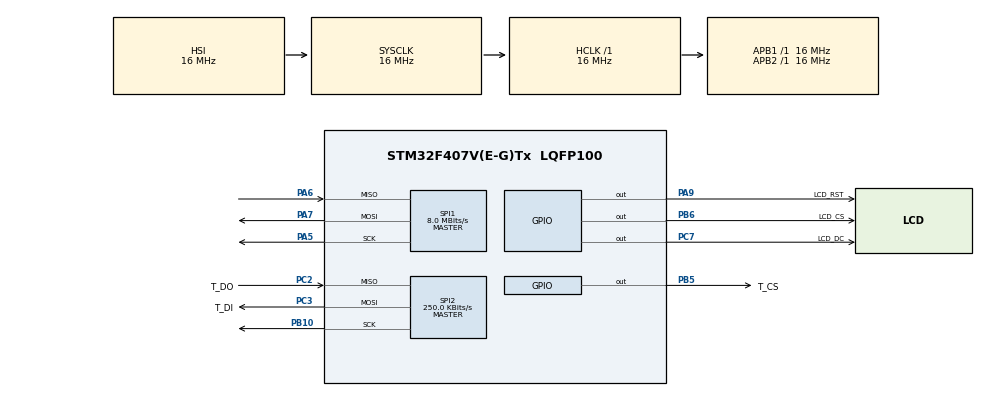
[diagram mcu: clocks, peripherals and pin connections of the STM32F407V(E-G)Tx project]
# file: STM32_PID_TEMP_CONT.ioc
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Mcu.Family=STM32F4
Mcu.Name=STM32F407V(E-G)Tx
Mcu.Package=LQFP100
NVIC.PriorityGroup=NVIC_PRIORITYGROUP_4
PA5.Mode=Full_Duplex_Master
PA5.Signal=SPI1_SCK
PA6.Mode=Full_Duplex_Master
PA6.Signal=SPI1_MISO
PA7.Mode=Full_Duplex_Master
PA7.Signal=SPI1_MOSI
PA9.GPIO_Label=LCD_RST
PA9.Signal=GPIO_Output
PB10.Mode=Full_Duplex_Master
PB10.Signal=SPI2_SCK
PB5.GPIO_Label=T_CS
PB5.Signal=GPIO_Output
PB6.GPIO_Label=LCD_CS
PB6.Signal=GPIO_Output
PC2.GPIO_Label=T_DO
PC2.Mode=Full_Duplex_Master
PC2.Signal=SPI2_MISO
PC3.GPIO_Label=T_DI
PC3.Mode=Full_Duplex_Master
PC3.Signal=SPI2_MOSI
PC7.GPIO_Label=LCD_DC
PC7.Signal=GPIO_Output
ProjectManager.HeapSize=0x200
ProjectManager.StackSize=0x400
ProjectManager.TargetToolchain=STM32CubeIDE
RCC.AHBFreq_Value=16000000
RCC.APB1Freq_Value=16000000
RCC.APB2Freq_Value=16000000
RCC.CortexFreq_Value=16000000
RCC.HSE_VALUE=25000000
RCC.HSI_VALUE=16000000
RCC.LSE_VALUE=32768
RCC.SYSCLKFreq_VALUE=16000000
RCC.VCOOutputFreq_Value=192000000
SPI1.CalculateBaudRate=8.0 MBits/s
SPI1.Direction=SPI_DIRECTION_2LINES
SPI1.Mode=SPI_MODE_MASTER
SPI1.VirtualType=VM_MASTER
SPI2.BaudRatePrescaler=SPI_BAUDRATEPRESCALER_64
SPI2.CalculateBaudRate=250.0 KBits/s
SPI2.Direction=SPI_DIRECTION_2LINES
SPI2.Mode=SPI_MODE_MASTER
SPI2.VirtualType=VM_MASTER
board=custom

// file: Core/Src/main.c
/* USER CODE BEGIN Header */
/**
  ******************************************************************************
  * @file           : main.c
  * @brief          : Main program body
  ******************************************************************************
  * @attention
  *
  * Copyright (c) 2024 STMicroelectronics.
  * All rights reserved.
  *
  * This software is licensed under terms that can be found in the LICENSE file
  * in the root directory of this software component.
  * If no LICENSE file comes with this software, it is provided AS-IS.
  *
  ******************************************************************************
  */
/* USER CODE END Header */
#include "main.h"
#include "stm32f4xx_hal.h"

/* USER CODE BEGIN Includes */
#include "MY_ILI9341.h"
#include "TSC2046.h"
/* USER CODE END Includes */

SPI_HandleTypeDef hspi1;
SPI_HandleTypeDef hspi2;

void SystemClock_Config(void);
static void MX_GPIO_Init(void);
static void MX_SPI1_Init(void);
static void MX_SPI2_Init(void);

int main(void)
{

  /* MCU Configuration--------------------------------------------------------*/

  /* Reset of all peripherals, Initializes the Flash interface and the Systick. */
  HAL_Init();

  /* Configure the system clock */
  SystemClock_Config();

  /* Initialize all configured peripherals */
  MX_GPIO_Init();
  MX_SPI1_Init();
  MX_SPI2_Init();
  /* USER CODE BEGIN 2 */
  ILI9341_Init(&hspi1, LCD_CS_GPIO_Port, LCD_CS_Pin, LCD_DC_GPIO_Port, LCD_DC_Pin, LCD_RST_GPIO_Port, LCD_RST_Pin);
  ILI9341_setRotation(2);
  ILI9341_Fill(COLOR_MAGENTA);

  /* USER CODE END 2 */

  /* Infinite loop */
  while (1)
  {

  }
}

void SystemClock_Config(void)
{
  RCC_OscInitTypeDef RCC_OscInitStruct = {0};
  RCC_ClkInitTypeDef RCC_ClkInitStruct = {0};

  /** Configure the main internal regulator output voltage
  */
  __HAL_RCC_PWR_CLK_ENABLE();
  __HAL_PWR_VOLTAGESCALING_CONFIG(PWR_REGULATOR_VOLTAGE_SCALE1);

  /** Initializes the RCC Oscillators according to the specified parameters
  * in the RCC_OscInitTypeDef structure.
  */
  RCC_OscInitStruct.OscillatorType = RCC_OSCILLATORTYPE_HSI;
  RCC_OscInitStruct.HSIState = RCC_HSI_ON;
  RCC_OscInitStruct.HSICalibrationValue = RCC_HSICALIBRATION_DEFAULT;
  RCC_OscInitStruct.PLL.PLLState = RCC_PLL_NONE;
  if (HAL_RCC_OscConfig(&RCC_OscInitStruct) != HAL_OK)
  {
    Error_Handler();
  }

  /** Initializes the CPU, AHB and APB buses clocks
  */
  RCC_ClkInitStruct.ClockType = RCC_CLOCKTYPE_HCLK|RCC_CLOCKTYPE_SYSCLK
                              |RCC_CLOCKTYPE_PCLK1|RCC_CLOCKTYPE_PCLK2;
  RCC_ClkInitStruct.SYSCLKSource = RCC_SYSCLKSOURCE_HSI;
  RCC_ClkInitStruct.AHBCLKDivider = RCC_SYSCLK_DIV1;
  RCC_ClkInitStruct.APB1CLKDivider = RCC_HCLK_DIV1;
  RCC_ClkInitStruct.APB2CLKDivider = RCC_HCLK_DIV1;

  if (HAL_RCC_ClockConfig(&RCC_ClkInitStruct, FLASH_LATENCY_0) != HAL_OK)
  {
    Error_Handler();
  }
}

static void MX_SPI1_Init(void)
{

  /* SPI1 parameter configuration*/
  hspi1.Instance = SPI1;
  hspi1.Init.Mode = SPI_MODE_MASTER;
  hspi1.Init.Direction = SPI_DIRECTION_2LINES;
  hspi1.Init.DataSize = SPI_DATASIZE_8BIT;
  hspi1.Init.CLKPolarity = SPI_POLARITY_LOW;
  hspi1.Init.CLKPhase = SPI_PHASE_1EDGE;
  hspi1.Init.NSS = SPI_NSS_SOFT;
  hspi1.Init.BaudRatePrescaler = SPI_BAUDRATEPRESCALER_2;
  hspi1.Init.FirstBit = SPI_FIRSTBIT_MSB;
  hspi1.Init.TIMode = SPI_TIMODE_DISABLE;
  hspi1.Init.CRCCalculation = SPI_CRCCALCULATION_DISABLE;
  hspi1.Init.CRCPolynomial = 10;
  if (HAL_SPI_Init(&hspi1) != HAL_OK)
  {
    Error_Handler();
  }

}

static void MX_SPI2_Init(void)
{

  /* SPI2 parameter configuration*/
  hspi2.Instance = SPI2;
  hspi2.Init.Mode = SPI_MODE_MASTER;
  hspi2.Init.Direction = SPI_DIRECTION_2LINES;
  hspi2.Init.DataSize = SPI_DATASIZE_8BIT;
  hspi2.Init.CLKPolarity = SPI_POLARITY_LOW;
  hspi2.Init.CLKPhase = SPI_PHASE_1EDGE;
  hspi2.Init.NSS = SPI_NSS_SOFT;
  hspi2.Init.BaudRatePrescaler = SPI_BAUDRATEPRESCALER_64;
  hspi2.Init.FirstBit = SPI_FIRSTBIT_MSB;
  hspi2.Init.TIMode = SPI_TIMODE_DISABLE;
  hspi2.Init.CRCCalculation = SPI_CRCCALCULATION_DISABLE;
  hspi2.Init.CRCPolynomial = 10;
  if (HAL_SPI_Init(&hspi2) != HAL_OK)
  {
    Error_Handler();
  }

}

static void MX_GPIO_Init(void)
{
  GPIO_InitTypeDef GPIO_InitStruct = {0};

  /* GPIO Ports Clock Enable */
  __HAL_RCC_GPIOC_CLK_ENABLE();
  __HAL_RCC_GPIOA_CLK_ENABLE();
  __HAL_RCC_GPIOB_CLK_ENABLE();

  /*Configure GPIO pin Output Level */
  HAL_GPIO_WritePin(LCD_DC_GPIO_Port, LCD_DC_Pin, GPIO_PIN_RESET);

  /*Configure GPIO pin Output Level */
  HAL_GPIO_WritePin(LCD_RST_GPIO_Port, LCD_RST_Pin, GPIO_PIN_RESET);

  /*Configure GPIO pin Output Level */
  HAL_GPIO_WritePin(GPIOB, T_CS_Pin|LCD_CS_Pin, GPIO_PIN_RESET);

  /*Configure GPIO pin : LCD_DC_Pin */
  GPIO_InitStruct.Pin = LCD_DC_Pin;
  GPIO_InitStruct.Mode = GPIO_MODE_OUTPUT_PP;
  GPIO_InitStruct.Pull = GPIO_NOPULL;
  GPIO_InitStruct.Speed = GPIO_SPEED_FREQ_LOW;
  HAL_GPIO_Init(LCD_DC_GPIO_Port, &GPIO_InitStruct);

  /*Configure GPIO pin : LCD_RST_Pin */
  GPIO_InitStruct.Pin = LCD_RST_Pin;
  GPIO_InitStruct.Mode = GPIO_MODE_OUTPUT_PP;
  GPIO_InitStruct.Pull = GPIO_NOPULL;
  GPIO_InitStruct.Speed = GPIO_SPEED_FREQ_LOW;
  HAL_GPIO_Init(LCD_RST_GPIO_Port, &GPIO_InitStruct);

  /*Configure GPIO pins : T_CS_Pin LCD_CS_Pin */
  GPIO_InitStruct.Pin = T_CS_Pin|LCD_CS_Pin;
  GPIO_InitStruct.Mode = GPIO_MODE_OUTPUT_PP;
  GPIO_InitStruct.Pull = GPIO_NOPULL;
  GPIO_InitStruct.Speed = GPIO_SPEED_FREQ_LOW;
  HAL_GPIO_Init(GPIOB, &GPIO_InitStruct);

}

void Error_Handler(void)
{
  __disable_irq();
  while (1)
  {
  }
}
